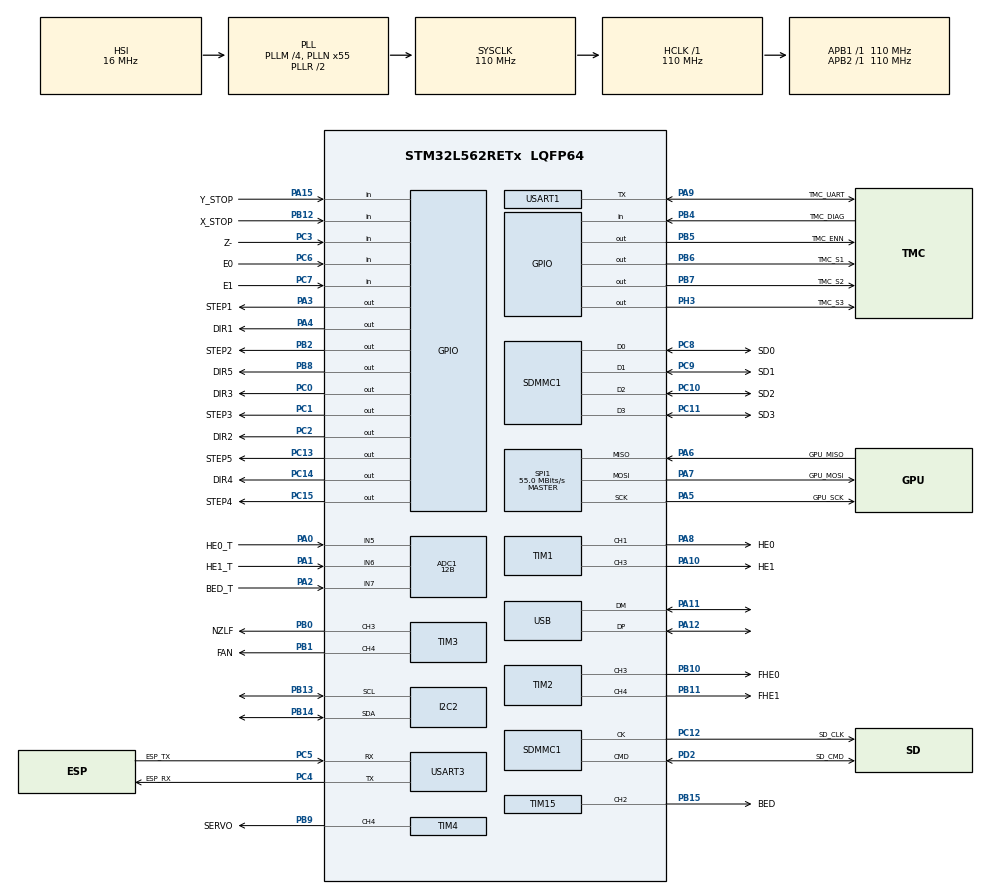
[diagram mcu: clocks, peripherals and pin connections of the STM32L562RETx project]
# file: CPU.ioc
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ADC1.Channel-0\#ChannelRegularConversion=ADC_CHANNEL_5
ADC1.Channel-1\#ChannelRegularConversion=ADC_CHANNEL_6
ADC1.Channel-2\#ChannelRegularConversion=ADC_CHANNEL_7
ADC1.Channel-3\#ChannelRegularConversion=ADC_CHANNEL_TEMPSENSOR
ADC1.Channel-4\#ChannelRegularConversion=ADC_CHANNEL_VBAT
ADC1.Channel-5\#ChannelRegularConversion=ADC_CHANNEL_VREFINT
ADC1.ContinuousConvMode=ENABLE
ADC1.DMAContinuousRequests=ENABLE
ADC1.NbrOfConversion=6
ADC1.NbrOfConversionFlag=1
ADC1.OffsetNumber-0\#ChannelRegularConversion=ADC_OFFSET_NONE
ADC1.OffsetNumber-1\#ChannelRegularConversion=ADC_OFFSET_NONE
ADC1.OffsetNumber-2\#ChannelRegularConversion=ADC_OFFSET_NONE
ADC1.OffsetNumber-3\#ChannelRegularConversion=ADC_OFFSET_NONE
ADC1.OffsetNumber-4\#ChannelRegularConversion=ADC_OFFSET_NONE
ADC1.OffsetNumber-5\#ChannelRegularConversion=ADC_OFFSET_NONE
ADC1.OversamplingMode=ENABLE
ADC1.Rank-0\#ChannelRegularConversion=1
ADC1.Rank-1\#ChannelRegularConversion=2
ADC1.Rank-2\#ChannelRegularConversion=3
ADC1.Rank-3\#ChannelRegularConversion=4
ADC1.Rank-4\#ChannelRegularConversion=5
ADC1.Rank-5\#ChannelRegularConversion=6
ADC1.Ratio=ADC_OVERSAMPLING_RATIO_16
ADC1.Resolution=ADC_RESOLUTION_12B
ADC1.SamplingTime-0\#ChannelRegularConversion=ADC_SAMPLETIME_640CYCLES_5
ADC1.SamplingTime-1\#ChannelRegularConversion=ADC_SAMPLETIME_640CYCLES_5
ADC1.SamplingTime-2\#ChannelRegularConversion=ADC_SAMPLETIME_640CYCLES_5
ADC1.SamplingTime-3\#ChannelRegularConversion=ADC_SAMPLETIME_640CYCLES_5
ADC1.SamplingTime-4\#ChannelRegularConversion=ADC_SAMPLETIME_640CYCLES_5
ADC1.SamplingTime-5\#ChannelRegularConversion=ADC_SAMPLETIME_640CYCLES_5
ADC1.master=1
Dma.ADC1.0.Channel_PRIV_NPRIV=DMA_CHANNEL_NPRIV_DISABLE
Dma.ADC1.0.Direction=DMA_PERIPH_TO_MEMORY
Dma.ADC1.0.EventEnable=DISABLE
Dma.ADC1.0.Instance=DMA1_Channel1
Dma.ADC1.0.MemDataAlignment=DMA_MDATAALIGN_WORD
Dma.ADC1.0.MemInc=DMA_MINC_ENABLE
Dma.ADC1.0.Mode=DMA_CIRCULAR
Dma.ADC1.0.PeriphDataAlignment=DMA_PDATAALIGN_WORD
Dma.ADC1.0.PeriphInc=DMA_PINC_DISABLE
Dma.ADC1.0.Polarity=HAL_DMAMUX_REQ_GEN_RISING
Dma.ADC1.0.Priority=DMA_PRIORITY_LOW
Dma.ADC1.0.RequestNumber=1
Dma.ADC1.0.SignalID=NONE
Dma.ADC1.0.SyncEnable=DISABLE
Dma.ADC1.0.SyncPolarity=HAL_DMAMUX_SYNC_NO_EVENT
Dma.ADC1.0.SyncRequestNumber=1
Dma.ADC1.0.SyncSignalID=NONE
Dma.Request0=ADC1
I2C2.Timing=0x40505681
Mcu.Family=STM32L5
Mcu.Name=STM32L562RETx
Mcu.Package=LQFP64
NVIC.DMA1_Channel1_IRQn=true\:0\:0\:false\:false\:true\:false\:true\:true
NVIC.PriorityGroup=NVIC_PRIORITYGROUP_3
NVIC.USB_FS_IRQn=true\:0\:0\:false\:false\:true\:false\:true\:true
PA0.GPIO_Label=HE0_T
PA0.Signal=ADCx_IN5
PA1.GPIO_Label=HE1_T
PA1.Signal=ADCx_IN6
PA10.GPIO_Label=HE1
PA10.Signal=S_TIM1_CH3
PA11.Mode=Device
PA11.Signal=USB_DM
PA12.Mode=Device
PA12.Signal=USB_DP
PA13\ (JTMS/SWDIO).Mode=Trace_Asynchronous_SW
PA13\ (JTMS/SWDIO).Signal=DEBUG_JTMS-SWDIO
PA14\ (JTCK/SWCLK).Mode=Trace_Asynchronous_SW
PA14\ (JTCK/SWCLK).Signal=DEBUG_JTCK-SWCLK
PA15\ (JTDI).GPIO_Label=Y_STOP
PA15\ (JTDI).Signal=GPIO_Input
PA2.GPIO_Label=BED_T
PA2.Signal=ADCx_IN7
PA3.GPIO_Label=STEP1
PA3.Signal=GPIO_Output
PA4.GPIO_Label=DIR1
PA4.Signal=GPIO_Output
PA5.GPIO_Label=GPU_SCK
PA5.Mode=Full_Duplex_Master
PA5.Signal=SPI1_SCK
PA6.GPIO_Label=GPU_MISO
PA6.Mode=Full_Duplex_Master
PA6.Signal=SPI1_MISO
PA7.GPIO_Label=GPU_MOSI
PA7.Mode=Full_Duplex_Master
PA7.Signal=SPI1_MOSI
PA8.GPIO_Label=HE0
PA8.Signal=S_TIM1_CH1
PA9.GPIO_Label=TMC_UART
PA9.Mode=Half_duplex(single_wire_mode)
PA9.Signal=USART1_TX
PB0.GPIO_Label=NZLF
PB0.Signal=S_TIM3_CH3
PB1.GPIO_Label=FAN
PB1.Signal=S_TIM3_CH4
PB10.GPIO_Label=FHE0
PB10.Signal=S_TIM2_CH3
PB11.GPIO_Label=FHE1
PB11.Signal=S_TIM2_CH4
PB12.GPIO_Label=X_STOP
PB12.Signal=GPIO_Input
PB13.Mode=I2C
PB13.Signal=I2C2_SCL
PB14.Mode=I2C
PB14.Signal=I2C2_SDA
PB15.GPIO_Label=BED
PB15.Signal=S_TIM15_CH2
PB2.GPIO_Label=STEP2
PB2.Signal=GPIO_Output
PB3\ (JTDO/TRACESWO).Mode=Trace_Asynchronous_SW
PB3\ (JTDO/TRACESWO).Signal=DEBUG_JTDO-SWO
PB4\ (NJTRST).GPIO_Label=TMC_DIAG
PB4\ (NJTRST).Signal=GPIO_Input
PB5.GPIO_Label=TMC_ENN
PB5.Signal=GPIO_Output
PB6.GPIO_Label=TMC_S1
PB6.Signal=GPIO_Output
PB7.GPIO_Label=TMC_S2
PB7.Signal=GPIO_Output
PB8.GPIO_Label=DIR5
PB8.Signal=GPIO_Output
PB9.GPIO_Label=SERVO
PB9.Signal=S_TIM4_CH4
PC0.GPIO_Label=DIR3
PC0.Signal=GPIO_Output
PC1.GPIO_Label=STEP3
PC1.Signal=GPIO_Output
PC10.GPIO_Label=SD2
PC10.Mode=mmc_4_bits_Wide_bus
PC10.Signal=SDMMC1_D2
PC11.GPIO_Label=SD3
PC11.Mode=mmc_4_bits_Wide_bus
PC11.Signal=SDMMC1_D3
PC12.GPIO_Label=SD_CLK
PC12.Mode=mmc_4_bits_Wide_bus
PC12.Signal=SDMMC1_CK
PC13.GPIO_Label=STEP5
PC13.Signal=GPIO_Output
PC14-OSC32_IN\ (PC14).GPIO_Label=DIR4
PC14-OSC32_IN\ (PC14).Signal=GPIO_Output
PC15-OSC32_OUT\ (PC15).GPIO_Label=STEP4
PC15-OSC32_OUT\ (PC15).Signal=GPIO_Output
PC2.GPIO_Label=DIR2
PC2.Signal=GPIO_Output
PC3.GPIO_Label=Z-
PC3.Signal=GPIO_Input
PC4.GPIO_Label=ESP_RX
PC4.Mode=Asynchronous
PC4.Signal=USART3_TX
PC5.GPIO_Label=ESP_TX
PC5.Mode=Asynchronous
PC5.Signal=USART3_RX
PC6.GPIO_Label=E0
PC6.Signal=GPIO_Input
PC7.GPIO_Label=E1
PC7.Signal=GPIO_Input
PC8.GPIO_Label=SD0
PC8.Mode=mmc_4_bits_Wide_bus
PC8.Signal=SDMMC1_D0
PC9.GPIO_Label=SD1
PC9.Mode=mmc_4_bits_Wide_bus
PC9.Signal=SDMMC1_D1
PD2.GPIO_Label=SD_CMD
PD2.Mode=mmc_4_bits_Wide_bus
PD2.Signal=SDMMC1_CMD
PH3-BOOT0.GPIO_Label=TMC_S3
PH3-BOOT0.Signal=GPIO_Output
ProjectManager.HeapSize=0x200
ProjectManager.StackSize=0x400
ProjectManager.TargetToolchain=STM32CubeIDE
RCC.ADCCLockSelection=RCC_ADCCLKSOURCE_SYSCLK
RCC.ADCFreq_Value=110000000
RCC.AHBFreq_Value=110000000
RCC.APB1Freq_Value=110000000
RCC.APB1TimFreq_Value=110000000
RCC.APB2Freq_Value=110000000
RCC.APB2TimFreq_Value=110000000
RCC.CortexFreq_Value=110000000
RCC.HCLKFreq_Value=110000000
RCC.HSE_VALUE=48000000
RCC.HSI48_VALUE=48000000
RCC.HSI_VALUE=16000000
RCC.LSE_VALUE=32768
RCC.MSIClockRange=RCC_MSIRANGE_11
RCC.MSI_VALUE=48000000
RCC.PLLM=4
RCC.PLLN=55
RCC.PLLSAI1M=6
RCC.PLLSAI1N=12
RCC.PLLSAI1Source=RCC_PLLSAI1SOURCE_HSE
RCC.PLLSourceVirtual=RCC_PLLSOURCE_HSI
RCC.SYSCLKFreq_VALUE=110000000
RCC.SYSCLKSource=RCC_SYSCLKSOURCE_PLLCLK
RCC.USBFreq_Value=48000000
RCC.VCOOutputFreq_Value=220000000
SH.ADCx_IN5.0=ADC1_IN5,IN5-Single-Ended
SH.ADCx_IN6.0=ADC1_IN6,IN6-Single-Ended
SH.ADCx_IN7.0=ADC1_IN7,IN7-Single-Ended
SH.S_TIM15_CH2.0=TIM15_CH2,PWM Generation2 CH2
SH.S_TIM1_CH1.0=TIM1_CH1,PWM Generation1 CH1
SH.S_TIM1_CH3.0=TIM1_CH3,PWM Generation3 CH3
SH.S_TIM2_CH3.0=TIM2_CH3,PWM Generation3 CH3
SH.S_TIM2_CH4.0=TIM2_CH4,PWM Generation4 CH4
SH.S_TIM3_CH3.0=TIM3_CH3,PWM Generation3 CH3
SH.S_TIM3_CH4.0=TIM3_CH4,PWM Generation4 CH4
SH.S_TIM4_CH4.0=TIM4_CH4,PWM Generation4 CH4
SPI1.BaudRatePrescaler=SPI_BAUDRATEPRESCALER_2
SPI1.CalculateBaudRate=55.0 MBits/s
SPI1.Direction=SPI_DIRECTION_2LINES
SPI1.Mode=SPI_MODE_MASTER
SPI1.VirtualType=VM_MASTER
TIM1.Channel-PWM\ Generation1\ CH1=TIM_CHANNEL_1
TIM1.Channel-PWM\ Generation3\ CH3=TIM_CHANNEL_3
TIM15.Channel-PWM\ Generation2\ CH2=TIM_CHANNEL_2
TIM2.Channel-PWM\ Generation3\ CH3=TIM_CHANNEL_3
TIM2.Channel-PWM\ Generation4\ CH4=TIM_CHANNEL_4
TIM3.Channel-PWM\ Generation3\ CH3=TIM_CHANNEL_3
TIM3.Channel-PWM\ Generation4\ CH4=TIM_CHANNEL_4
TIM4.Channel-PWM\ Generation4\ CH4=TIM_CHANNEL_4
USART1.VirtualMode-Half_duplex(single_wire_mode)=VM_ASYNC
USART3.VirtualMode-Asynchronous=VM_ASYNC
USB_DEVICE.CLASS_NAME_FS=CDC
USB_DEVICE.VirtualMode=Cdc
USB_DEVICE.VirtualModeFS=Cdc_FS
VP_ADC1_TempSens_Input.Mode=IN-TempSens
VP_ADC1_Vbat_Input.Mode=IN-Vbat
VP_ADC1_Vref_Input.Mode=IN-Vrefint
VP_PWR_VS_DBSignals.Mode=DisableDeadBatterySignals
VP_PWR_VS_SECSignals.Mode=Security/Privilege
VP_USB_DEVICE_VS_USB_DEVICE_CDC_FS.Mode=CDC_FS
board=custom

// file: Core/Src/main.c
/* USER CODE BEGIN Header */
/**
  ******************************************************************************
  * @file           : main.c
  * @brief          : Main program body
  ******************************************************************************
  * @attention
  *
  * Copyright (c) 2023 STMicroelectronics.
  * All rights reserved.
  *
  * This software is licensed under terms that can be found in the LICENSE file
  * in the root directory of this software component.
  * If no LICENSE file comes with this software, it is provided AS-IS.
  *
  ******************************************************************************
  */
/* USER CODE END Header */
#include "main.h"
#include "usb_device.h"

/* USER CODE BEGIN Includes */
#include <stdio.h>
#include <string.h>
#include <ctype.h>
#include <stdarg.h>
/* USER CODE END Includes */

/* USER CODE BEGIN PD */
#define ADC_CHANNELS 6
/* USER CODE END PD */

ADC_HandleTypeDef hadc1;
DMA_HandleTypeDef hdma_adc1;

I2C_HandleTypeDef hi2c2;

MMC_HandleTypeDef hmmc1;

SPI_HandleTypeDef hspi1;

TIM_HandleTypeDef htim1;
TIM_HandleTypeDef htim2;
TIM_HandleTypeDef htim3;
TIM_HandleTypeDef htim4;
TIM_HandleTypeDef htim15;

UART_HandleTypeDef huart1;
UART_HandleTypeDef huart3;

/* USER CODE BEGIN PV */
uint32_t value[ADC_CHANNELS];
/* USER CODE END PV */

void SystemClock_Config(void);
static void MX_GPIO_Init(void);
static void MX_DMA_Init(void);
static void MX_I2C2_Init(void);
static void MX_SDMMC1_MMC_Init(void);
static void MX_SPI1_Init(void);
static void MX_TIM1_Init(void);
static void MX_TIM2_Init(void);
static void MX_TIM3_Init(void);
static void MX_TIM4_Init(void);
static void MX_TIM15_Init(void);
static void MX_USART1_UART_Init(void);
static void MX_USART3_UART_Init(void);
static void MX_ADC1_Init(void);

int main(void)
{

  /* MCU Configuration--------------------------------------------------------*/

  /* Reset of all peripherals, Initializes the Flash interface and the Systick. */
  HAL_Init();

  /* Configure the system clock */
  SystemClock_Config();

  /* Initialize all configured peripherals */
  MX_GPIO_Init();
  MX_DMA_Init();
  MX_I2C2_Init();
  MX_SDMMC1_MMC_Init();
  MX_SPI1_Init();
  MX_TIM1_Init();
  MX_TIM2_Init();
  MX_TIM3_Init();
  MX_TIM4_Init();
  MX_TIM15_Init();
  MX_USART1_UART_Init();
  MX_USART3_UART_Init();
  MX_ADC1_Init();
  MX_USB_Device_Init();
  /* USER CODE BEGIN 2 */
//  HAL_ADC_Start_DMA(&hadc1, value, ADC_CHANNELS);
  /* USER CODE END 2 */

  /* Infinite loop */
  /* USER CODE BEGIN WHILE */
  while (1)
  {
//	  uint8_t Test[] = "Hello World !!!\r\n"; //Data to send
//	  HAL_UART_Transmit(&huart3,value[0],sizeof(value[0]),10);// Sending in normal mode
	  HAL_Delay(1000);
    /* USER CODE END WHILE */

  }
}

void SystemClock_Config(void)
{
  RCC_OscInitTypeDef RCC_OscInitStruct = {0};
  RCC_ClkInitTypeDef RCC_ClkInitStruct = {0};

  /** Configure the main internal regulator output voltage
  */
  if (HAL_PWREx_ControlVoltageScaling(PWR_REGULATOR_VOLTAGE_SCALE0) != HAL_OK)
  {
    Error_Handler();
  }

  /** Initializes the RCC Oscillators according to the specified parameters
  * in the RCC_OscInitTypeDef structure.
  */
  RCC_OscInitStruct.OscillatorType = RCC_OSCILLATORTYPE_HSI|RCC_OSCILLATORTYPE_HSE;
  RCC_OscInitStruct.HSEState = RCC_HSE_OFF;
  RCC_OscInitStruct.HSIState = RCC_HSI_ON;
  RCC_OscInitStruct.HSICalibrationValue = RCC_HSICALIBRATION_DEFAULT;
  RCC_OscInitStruct.PLL.PLLState = RCC_PLL_ON;
  RCC_OscInitStruct.PLL.PLLSource = RCC_PLLSOURCE_HSI;
  RCC_OscInitStruct.PLL.PLLM = 4;
  RCC_OscInitStruct.PLL.PLLN = 55;
  RCC_OscInitStruct.PLL.PLLP = RCC_PLLP_DIV7;
  RCC_OscInitStruct.PLL.PLLQ = RCC_PLLQ_DIV2;
  RCC_OscInitStruct.PLL.PLLR = RCC_PLLR_DIV2;
  if (HAL_RCC_OscConfig(&RCC_OscInitStruct) != HAL_OK)
  {
    Error_Handler();
  }

  /** Initializes the CPU, AHB and APB buses clocks
  */
  RCC_ClkInitStruct.ClockType = RCC_CLOCKTYPE_HCLK|RCC_CLOCKTYPE_SYSCLK
                              |RCC_CLOCKTYPE_PCLK1|RCC_CLOCKTYPE_PCLK2;
  RCC_ClkInitStruct.SYSCLKSource = RCC_SYSCLKSOURCE_PLLCLK;
  RCC_ClkInitStruct.AHBCLKDivider = RCC_SYSCLK_DIV1;
  RCC_ClkInitStruct.APB1CLKDivider = RCC_HCLK_DIV1;
  RCC_ClkInitStruct.APB2CLKDivider = RCC_HCLK_DIV1;

  if (HAL_RCC_ClockConfig(&RCC_ClkInitStruct, FLASH_LATENCY_5) != HAL_OK)
  {
    Error_Handler();
  }
}

static void MX_ADC1_Init(void)
{

  ADC_MultiModeTypeDef multimode = {0};
  ADC_ChannelConfTypeDef sConfig = {0};

  /** Common config
  */
  hadc1.Instance = ADC1;
  hadc1.Init.ClockPrescaler = ADC_CLOCK_ASYNC_DIV1;
  hadc1.Init.Resolution = ADC_RESOLUTION_12B;
  hadc1.Init.DataAlign = ADC_DATAALIGN_RIGHT;
  hadc1.Init.ScanConvMode = ADC_SCAN_ENABLE;
  hadc1.Init.EOCSelection = ADC_EOC_SINGLE_CONV;
  hadc1.Init.LowPowerAutoWait = DISABLE;
  hadc1.Init.ContinuousConvMode = ENABLE;
  hadc1.Init.NbrOfConversion = 6;
  hadc1.Init.DiscontinuousConvMode = DISABLE;
  hadc1.Init.ExternalTrigConv = ADC_SOFTWARE_START;
  hadc1.Init.ExternalTrigConvEdge = ADC_EXTERNALTRIGCONVEDGE_NONE;
  hadc1.Init.DMAContinuousRequests = ENABLE;
  hadc1.Init.Overrun = ADC_OVR_DATA_PRESERVED;
  hadc1.Init.OversamplingMode = ENABLE;
  hadc1.Init.Oversampling.Ratio = ADC_OVERSAMPLING_RATIO_16;
  hadc1.Init.Oversampling.RightBitShift = ADC_RIGHTBITSHIFT_NONE;
  hadc1.Init.Oversampling.TriggeredMode = ADC_TRIGGEREDMODE_SINGLE_TRIGGER;
  hadc1.Init.Oversampling.OversamplingStopReset = ADC_REGOVERSAMPLING_CONTINUED_MODE;
  if (HAL_ADC_Init(&hadc1) != HAL_OK)
  {
    Error_Handler();
  }

  /** Configure the ADC multi-mode
  */
  multimode.Mode = ADC_MODE_INDEPENDENT;
  if (HAL_ADCEx_MultiModeConfigChannel(&hadc1, &multimode) != HAL_OK)
  {
    Error_Handler();
  }

  /** Configure Regular Channel
  */
  sConfig.Channel = ADC_CHANNEL_5;
  sConfig.Rank = ADC_REGULAR_RANK_1;
  sConfig.SamplingTime = ADC_SAMPLETIME_640CYCLES_5;
  sConfig.SingleDiff = ADC_SINGLE_ENDED;
  sConfig.OffsetNumber = ADC_OFFSET_NONE;
  sConfig.Offset = 0;
  if (HAL_ADC_ConfigChannel(&hadc1, &sConfig) != HAL_OK)
  {
    Error_Handler();
  }

  /** Configure Regular Channel
  */
  sConfig.Channel = ADC_CHANNEL_6;
  sConfig.Rank = ADC_REGULAR_RANK_2;
  if (HAL_ADC_ConfigChannel(&hadc1, &sConfig) != HAL_OK)
  {
    Error_Handler();
  }

  /** Configure Regular Channel
  */
  sConfig.Channel = ADC_CHANNEL_7;
  sConfig.Rank = ADC_REGULAR_RANK_3;
  if (HAL_ADC_ConfigChannel(&hadc1, &sConfig) != HAL_OK)
  {
    Error_Handler();
  }

  /** Configure Regular Channel
  */
  sConfig.Channel = ADC_CHANNEL_TEMPSENSOR;
  sConfig.Rank = ADC_REGULAR_RANK_4;
  if (HAL_ADC_ConfigChannel(&hadc1, &sConfig) != HAL_OK)
  {
    Error_Handler();
  }

  /** Configure Regular Channel
  */
  sConfig.Channel = ADC_CHANNEL_VBAT;
  sConfig.Rank = ADC_REGULAR_RANK_5;
  if (HAL_ADC_ConfigChannel(&hadc1, &sConfig) != HAL_OK)
  {
    Error_Handler();
  }

  /** Configure Regular Channel
  */
  sConfig.Channel = ADC_CHANNEL_VREFINT;
  sConfig.Rank = ADC_REGULAR_RANK_6;
  if (HAL_ADC_ConfigChannel(&hadc1, &sConfig) != HAL_OK)
  {
    Error_Handler();
  }

}

static void MX_I2C2_Init(void)
{

  hi2c2.Instance = I2C2;
  hi2c2.Init.Timing = 0x40505681;
  hi2c2.Init.OwnAddress1 = 0;
  hi2c2.Init.AddressingMode = I2C_ADDRESSINGMODE_7BIT;
  hi2c2.Init.DualAddressMode = I2C_DUALADDRESS_DISABLE;
  hi2c2.Init.OwnAddress2 = 0;
  hi2c2.Init.OwnAddress2Masks = I2C_OA2_NOMASK;
  hi2c2.Init.GeneralCallMode = I2C_GENERALCALL_DISABLE;
  hi2c2.Init.NoStretchMode = I2C_NOSTRETCH_DISABLE;
  if (HAL_I2C_Init(&hi2c2) != HAL_OK)
  {
    Error_Handler();
  }

  /** Configure Analogue filter
  */
  if (HAL_I2CEx_ConfigAnalogFilter(&hi2c2, I2C_ANALOGFILTER_ENABLE) != HAL_OK)
  {
    Error_Handler();
  }

  /** Configure Digital filter
  */
  if (HAL_I2CEx_ConfigDigitalFilter(&hi2c2, 0) != HAL_OK)
  {
    Error_Handler();
  }

}

static void MX_SDMMC1_MMC_Init(void)
{

  hmmc1.Instance = SDMMC1;
  hmmc1.Init.ClockEdge = SDMMC_CLOCK_EDGE_RISING;
  hmmc1.Init.ClockPowerSave = SDMMC_CLOCK_POWER_SAVE_DISABLE;
  hmmc1.Init.BusWide = SDMMC_BUS_WIDE_4B;
  hmmc1.Init.HardwareFlowControl = SDMMC_HARDWARE_FLOW_CONTROL_DISABLE;
  hmmc1.Init.ClockDiv = 0;
  if (HAL_MMC_Init(&hmmc1) != HAL_OK)
  {
    Error_Handler();
  }

}

static void MX_SPI1_Init(void)
{

  /* SPI1 parameter configuration*/
  hspi1.Instance = SPI1;
  hspi1.Init.Mode = SPI_MODE_MASTER;
  hspi1.Init.Direction = SPI_DIRECTION_2LINES;
  hspi1.Init.DataSize = SPI_DATASIZE_4BIT;
  hspi1.Init.CLKPolarity = SPI_POLARITY_LOW;
  hspi1.Init.CLKPhase = SPI_PHASE_1EDGE;
  hspi1.Init.NSS = SPI_NSS_SOFT;
  hspi1.Init.BaudRatePrescaler = SPI_BAUDRATEPRESCALER_2;
  hspi1.Init.FirstBit = SPI_FIRSTBIT_MSB;
  hspi1.Init.TIMode = SPI_TIMODE_DISABLE;
  hspi1.Init.CRCCalculation = SPI_CRCCALCULATION_DISABLE;
  hspi1.Init.CRCPolynomial = 7;
  hspi1.Init.CRCLength = SPI_CRC_LENGTH_DATASIZE;
  hspi1.Init.NSSPMode = SPI_NSS_PULSE_ENABLE;
  if (HAL_SPI_Init(&hspi1) != HAL_OK)
  {
    Error_Handler();
  }

}

static void MX_TIM1_Init(void)
{

  TIM_MasterConfigTypeDef sMasterConfig = {0};
  TIM_OC_InitTypeDef sConfigOC = {0};
  TIM_BreakDeadTimeConfigTypeDef sBreakDeadTimeConfig = {0};

  htim1.Instance = TIM1;
  htim1.Init.Prescaler = 0;
  htim1.Init.CounterMode = TIM_COUNTERMODE_UP;
  htim1.Init.Period = 65535;
  htim1.Init.ClockDivision = TIM_CLOCKDIVISION_DIV1;
  htim1.Init.RepetitionCounter = 0;
  htim1.Init.AutoReloadPreload = TIM_AUTORELOAD_PRELOAD_DISABLE;
  if (HAL_TIM_PWM_Init(&htim1) != HAL_OK)
  {
    Error_Handler();
  }
  sMasterConfig.MasterOutputTrigger = TIM_TRGO_RESET;
  sMasterConfig.MasterOutputTrigger2 = TIM_TRGO2_RESET;
  sMasterConfig.MasterSlaveMode = TIM_MASTERSLAVEMODE_DISABLE;
  if (HAL_TIMEx_MasterConfigSynchronization(&htim1, &sMasterConfig) != HAL_OK)
  {
    Error_Handler();
  }
  sConfigOC.OCMode = TIM_OCMODE_PWM1;
  sConfigOC.Pulse = 0;
  sConfigOC.OCPolarity = TIM_OCPOLARITY_HIGH;
  sConfigOC.OCNPolarity = TIM_OCNPOLARITY_HIGH;
  sConfigOC.OCFastMode = TIM_OCFAST_DISABLE;
  sConfigOC.OCIdleState = TIM_OCIDLESTATE_RESET;
  sConfigOC.OCNIdleState = TIM_OCNIDLESTATE_RESET;
  if (HAL_TIM_PWM_ConfigChannel(&htim1, &sConfigOC, TIM_CHANNEL_1) != HAL_OK)
  {
    Error_Handler();
  }
  if (HAL_TIM_PWM_ConfigChannel(&htim1, &sConfigOC, TIM_CHANNEL_3) != HAL_OK)
  {
    Error_Handler();
  }
  sBreakDeadTimeConfig.OffStateRunMode = TIM_OSSR_DISABLE;
  sBreakDeadTimeConfig.OffStateIDLEMode = TIM_OSSI_DISABLE;
  sBreakDeadTimeConfig.LockLevel = TIM_LOCKLEVEL_OFF;
  sBreakDeadTimeConfig.DeadTime = 0;
  sBreakDeadTimeConfig.BreakState = TIM_BREAK_DISABLE;
  sBreakDeadTimeConfig.BreakPolarity = TIM_BREAKPOLARITY_HIGH;
  sBreakDeadTimeConfig.BreakFilter = 0;
  sBreakDeadTimeConfig.BreakAFMode = TIM_BREAK_AFMODE_INPUT;
  sBreakDeadTimeConfig.Break2State = TIM_BREAK2_DISABLE;
  sBreakDeadTimeConfig.Break2Polarity = TIM_BREAK2POLARITY_HIGH;
  sBreakDeadTimeConfig.Break2Filter = 0;
  sBreakDeadTimeConfig.Break2AFMode = TIM_BREAK_AFMODE_INPUT;
  sBreakDeadTimeConfig.AutomaticOutput = TIM_AUTOMATICOUTPUT_DISABLE;
  if (HAL_TIMEx_ConfigBreakDeadTime(&htim1, &sBreakDeadTimeConfig) != HAL_OK)
  {
    Error_Handler();
  }
  HAL_TIM_MspPostInit(&htim1);

}

static void MX_TIM2_Init(void)
{

  TIM_MasterConfigTypeDef sMasterConfig = {0};
  TIM_OC_InitTypeDef sConfigOC = {0};

  htim2.Instance = TIM2;
  htim2.Init.Prescaler = 0;
  htim2.Init.CounterMode = TIM_COUNTERMODE_UP;
  htim2.Init.Period = 4294967295;
  htim2.Init.ClockDivision = TIM_CLOCKDIVISION_DIV1;
  htim2.Init.AutoReloadPreload = TIM_AUTORELOAD_PRELOAD_DISABLE;
  if (HAL_TIM_PWM_Init(&htim2) != HAL_OK)
  {
    Error_Handler();
  }
  sMasterConfig.MasterOutputTrigger = TIM_TRGO_RESET;
  sMasterConfig.MasterSlaveMode = TIM_MASTERSLAVEMODE_DISABLE;
  if (HAL_TIMEx_MasterConfigSynchronization(&htim2, &sMasterConfig) != HAL_OK)
  {
    Error_Handler();
  }
  sConfigOC.OCMode = TIM_OCMODE_PWM1;
  sConfigOC.Pulse = 0;
  sConfigOC.OCPolarity = TIM_OCPOLARITY_HIGH;
  sConfigOC.OCFastMode = TIM_OCFAST_DISABLE;
  if (HAL_TIM_PWM_ConfigChannel(&htim2, &sConfigOC, TIM_CHANNEL_3) != HAL_OK)
  {
    Error_Handler();
  }
  if (HAL_TIM_PWM_ConfigChannel(&htim2, &sConfigOC, TIM_CHANNEL_4) != HAL_OK)
  {
    Error_Handler();
  }
  HAL_TIM_MspPostInit(&htim2);

}

static void MX_TIM3_Init(void)
{

  TIM_MasterConfigTypeDef sMasterConfig = {0};
  TIM_OC_InitTypeDef sConfigOC = {0};

  htim3.Instance = TIM3;
  htim3.Init.Prescaler = 0;
  htim3.Init.CounterMode = TIM_COUNTERMODE_UP;
  htim3.Init.Period = 65535;
  htim3.Init.ClockDivision = TIM_CLOCKDIVISION_DIV1;
  htim3.Init.AutoReloadPreload = TIM_AUTORELOAD_PRELOAD_DISABLE;
  if (HAL_TIM_PWM_Init(&htim3) != HAL_OK)
  {
    Error_Handler();
  }
  sMasterConfig.MasterOutputTrigger = TIM_TRGO_RESET;
  sMasterConfig.MasterSlaveMode = TIM_MASTERSLAVEMODE_DISABLE;
  if (HAL_TIMEx_MasterConfigSynchronization(&htim3, &sMasterConfig) != HAL_OK)
  {
    Error_Handler();
  }
  sConfigOC.OCMode = TIM_OCMODE_PWM1;
  sConfigOC.Pulse = 0;
  sConfigOC.OCPolarity = TIM_OCPOLARITY_HIGH;
  sConfigOC.OCFastMode = TIM_OCFAST_DISABLE;
  if (HAL_TIM_PWM_ConfigChannel(&htim3, &sConfigOC, TIM_CHANNEL_3) != HAL_OK)
  {
    Error_Handler();
  }
  if (HAL_TIM_PWM_ConfigChannel(&htim3, &sConfigOC, TIM_CHANNEL_4) != HAL_OK)
  {
    Error_Handler();
  }
  HAL_TIM_MspPostInit(&htim3);

}

static void MX_TIM4_Init(void)
{

  TIM_MasterConfigTypeDef sMasterConfig = {0};
  TIM_OC_InitTypeDef sConfigOC = {0};

  htim4.Instance = TIM4;
  htim4.Init.Prescaler = 0;
  htim4.Init.CounterMode = TIM_COUNTERMODE_UP;
  htim4.Init.Period = 65535;
  htim4.Init.ClockDivision = TIM_CLOCKDIVISION_DIV1;
  htim4.Init.AutoReloadPreload = TIM_AUTORELOAD_PRELOAD_DISABLE;
  if (HAL_TIM_PWM_Init(&htim4) != HAL_OK)
  {
    Error_Handler();
  }
  sMasterConfig.MasterOutputTrigger = TIM_TRGO_RESET;
  sMasterConfig.MasterSlaveMode = TIM_MASTERSLAVEMODE_DISABLE;
  if (HAL_TIMEx_MasterConfigSynchronization(&htim4, &sMasterConfig) != HAL_OK)
  {
    Error_Handler();
  }
  sConfigOC.OCMode = TIM_OCMODE_PWM1;
  sConfigOC.Pulse = 0;
  sConfigOC.OCPolarity = TIM_OCPOLARITY_HIGH;
  sConfigOC.OCFastMode = TIM_OCFAST_DISABLE;
  if (HAL_TIM_PWM_ConfigChannel(&htim4, &sConfigOC, TIM_CHANNEL_4) != HAL_OK)
  {
    Error_Handler();
  }
  HAL_TIM_MspPostInit(&htim4);

}

static void MX_TIM15_Init(void)
{

  TIM_MasterConfigTypeDef sMasterConfig = {0};
  TIM_OC_InitTypeDef sConfigOC = {0};
  TIM_BreakDeadTimeConfigTypeDef sBreakDeadTimeConfig = {0};

  htim15.Instance = TIM15;
  htim15.Init.Prescaler = 0;
  htim15.Init.CounterMode = TIM_COUNTERMODE_UP;
  htim15.Init.Period = 65535;
  htim15.Init.ClockDivision = TIM_CLOCKDIVISION_DIV1;
  htim15.Init.RepetitionCounter = 0;
  htim15.Init.AutoReloadPreload = TIM_AUTORELOAD_PRELOAD_DISABLE;
  if (HAL_TIM_PWM_Init(&htim15) != HAL_OK)
  {
    Error_Handler();
  }
  sMasterConfig.MasterOutputTrigger = TIM_TRGO_RESET;
  sMasterConfig.MasterSlaveMode = TIM_MASTERSLAVEMODE_DISABLE;
  if (HAL_TIMEx_MasterConfigSynchronization(&htim15, &sMasterConfig) != HAL_OK)
  {
    Error_Handler();
  }
  sConfigOC.OCMode = TIM_OCMODE_PWM1;
  sConfigOC.Pulse = 0;
  sConfigOC.OCPolarity = TIM_OCPOLARITY_HIGH;
  sConfigOC.OCNPolarity = TIM_OCNPOLARITY_HIGH;
  sConfigOC.OCFastMode = TIM_OCFAST_DISABLE;
  sConfigOC.OCIdleState = TIM_OCIDLESTATE_RESET;
  sConfigOC.OCNIdleState = TIM_OCNIDLESTATE_RESET;
  if (HAL_TIM_PWM_ConfigChannel(&htim15, &sConfigOC, TIM_CHANNEL_2) != HAL_OK)
  {
    Error_Handler();
  }
  sBreakDeadTimeConfig.OffStateRunMode = TIM_OSSR_DISABLE;
  sBreakDeadTimeConfig.OffStateIDLEMode = TIM_OSSI_DISABLE;
  sBreakDeadTimeConfig.LockLevel = TIM_LOCKLEVEL_OFF;
  sBreakDeadTimeConfig.DeadTime = 0;
  sBreakDeadTimeConfig.BreakState = TIM_BREAK_DISABLE;
  sBreakDeadTimeConfig.BreakPolarity = TIM_BREAKPOLARITY_HIGH;
  sBreakDeadTimeConfig.BreakFilter = 0;
  sBreakDeadTimeConfig.AutomaticOutput = TIM_AUTOMATICOUTPUT_DISABLE;
  if (HAL_TIMEx_ConfigBreakDeadTime(&htim15, &sBreakDeadTimeConfig) != HAL_OK)
  {
    Error_Handler();
  }
  HAL_TIM_MspPostInit(&htim15);

}

static void MX_USART1_UART_Init(void)
{

  huart1.Instance = USART1;
  huart1.Init.BaudRate = 115200;
  huart1.Init.WordLength = UART_WORDLENGTH_8B;
  huart1.Init.StopBits = UART_STOPBITS_1;
  huart1.Init.Parity = UART_PARITY_NONE;
  huart1.Init.Mode = UART_MODE_TX_RX;
  huart1.Init.HwFlowCtl = UART_HWCONTROL_NONE;
  huart1.Init.OverSampling = UART_OVERSAMPLING_16;
  huart1.Init.OneBitSampling = UART_ONE_BIT_SAMPLE_DISABLE;
  huart1.Init.ClockPrescaler = UART_PRESCALER_DIV1;
  huart1.AdvancedInit.AdvFeatureInit = UART_ADVFEATURE_NO_INIT;
  if (HAL_HalfDuplex_Init(&huart1) != HAL_OK)
  {
    Error_Handler();
  }
  if (HAL_UARTEx_SetTxFifoThreshold(&huart1, UART_TXFIFO_THRESHOLD_1_8) != HAL_OK)
  {
    Error_Handler();
  }
  if (HAL_UARTEx_SetRxFifoThreshold(&huart1, UART_RXFIFO_THRESHOLD_1_8) != HAL_OK)
  {
    Error_Handler();
  }
  if (HAL_UARTEx_DisableFifoMode(&huart1) != HAL_OK)
  {
    Error_Handler();
  }

}

static void MX_USART3_UART_Init(void)
{

  huart3.Instance = USART3;
  huart3.Init.BaudRate = 115200;
  huart3.Init.WordLength = UART_WORDLENGTH_8B;
  huart3.Init.StopBits = UART_STOPBITS_1;
  huart3.Init.Parity = UART_PARITY_NONE;
  huart3.Init.Mode = UART_MODE_TX_RX;
  huart3.Init.HwFlowCtl = UART_HWCONTROL_NONE;
  huart3.Init.OverSampling = UART_OVERSAMPLING_16;
  huart3.Init.OneBitSampling = UART_ONE_BIT_SAMPLE_DISABLE;
  huart3.Init.ClockPrescaler = UART_PRESCALER_DIV1;
  huart3.AdvancedInit.AdvFeatureInit = UART_ADVFEATURE_NO_INIT;
  if (HAL_UART_Init(&huart3) != HAL_OK)
  {
    Error_Handler();
  }
  if (HAL_UARTEx_SetTxFifoThreshold(&huart3, UART_TXFIFO_THRESHOLD_1_8) != HAL_OK)
  {
    Error_Handler();
  }
  if (HAL_UARTEx_SetRxFifoThreshold(&huart3, UART_RXFIFO_THRESHOLD_1_8) != HAL_OK)
  {
    Error_Handler();
  }
  if (HAL_UARTEx_DisableFifoMode(&huart3) != HAL_OK)
  {
    Error_Handler();
  }

}

static void MX_DMA_Init(void)
{

  /* DMA controller clock enable */
  __HAL_RCC_DMAMUX1_CLK_ENABLE();
  __HAL_RCC_DMA1_CLK_ENABLE();

  /* DMA interrupt init */
  /* DMA1_Channel1_IRQn interrupt configuration */
  HAL_NVIC_SetPriority(DMA1_Channel1_IRQn, 0, 0);
  HAL_NVIC_EnableIRQ(DMA1_Channel1_IRQn);

}

static void MX_GPIO_Init(void)
{
  GPIO_InitTypeDef GPIO_InitStruct = {0};

  /* GPIO Ports Clock Enable */
  __HAL_RCC_GPIOC_CLK_ENABLE();
  __HAL_RCC_GPIOA_CLK_ENABLE();
  __HAL_RCC_GPIOB_CLK_ENABLE();
  __HAL_RCC_GPIOD_CLK_ENABLE();
  __HAL_RCC_GPIOH_CLK_ENABLE();

  /*Configure GPIO pin Output Level */
  HAL_GPIO_WritePin(GPIOC, STEP5_Pin|DIR4_Pin|STEP4_Pin|DIR3_Pin
                          |STEP3_Pin|DIR2_Pin, GPIO_PIN_RESET);

  /*Configure GPIO pin Output Level */
  HAL_GPIO_WritePin(GPIOA, STEP1_Pin|DIR1_Pin, GPIO_PIN_RESET);

  /*Configure GPIO pin Output Level */
  HAL_GPIO_WritePin(GPIOB, STEP2_Pin|TMC_ENN_Pin|TMC_S1_Pin|TMC_S2_Pin
                          |DIR5_Pin, GPIO_PIN_RESET);

  /*Configure GPIO pin Output Level */
  HAL_GPIO_WritePin(TMC_S3_GPIO_Port, TMC_S3_Pin, GPIO_PIN_RESET);

  /*Configure GPIO pins : STEP5_Pin DIR4_Pin STEP4_Pin DIR3_Pin
                           STEP3_Pin DIR2_Pin */
  GPIO_InitStruct.Pin = STEP5_Pin|DIR4_Pin|STEP4_Pin|DIR3_Pin
                          |STEP3_Pin|DIR2_Pin;
  GPIO_InitStruct.Mode = GPIO_MODE_OUTPUT_PP;
  GPIO_InitStruct.Pull = GPIO_NOPULL;
  GPIO_InitStruct.Speed = GPIO_SPEED_FREQ_LOW;
  HAL_GPIO_Init(GPIOC, &GPIO_InitStruct);

  /*Configure GPIO pins : Z__Pin E0_Pin E1_Pin */
  GPIO_InitStruct.Pin = Z__Pin|E0_Pin|E1_Pin;
  GPIO_InitStruct.Mode = GPIO_MODE_INPUT;
  GPIO_InitStruct.Pull = GPIO_NOPULL;
  HAL_GPIO_Init(GPIOC, &GPIO_InitStruct);

  /*Configure GPIO pins : STEP1_Pin DIR1_Pin */
  GPIO_InitStruct.Pin = STEP1_Pin|DIR1_Pin;
  GPIO_InitStruct.Mode = GPIO_MODE_OUTPUT_PP;
  GPIO_InitStruct.Pull = GPIO_NOPULL;
  GPIO_InitStruct.Speed = GPIO_SPEED_FREQ_LOW;
  HAL_GPIO_Init(GPIOA, &GPIO_InitStruct);

  /*Configure GPIO pins : STEP2_Pin TMC_ENN_Pin TMC_S1_Pin TMC_S2_Pin
                           DIR5_Pin */
  GPIO_InitStruct.Pin = STEP2_Pin|TMC_ENN_Pin|TMC_S1_Pin|TMC_S2_Pin
                          |DIR5_Pin;
  GPIO_InitStruct.Mode = GPIO_MODE_OUTPUT_PP;
  GPIO_InitStruct.Pull = GPIO_NOPULL;
  GPIO_InitStruct.Speed = GPIO_SPEED_FREQ_LOW;
  HAL_GPIO_Init(GPIOB, &GPIO_InitStruct);

  /*Configure GPIO pins : X_STOP_Pin TMC_DIAG_Pin */
  GPIO_InitStruct.Pin = X_STOP_Pin|TMC_DIAG_Pin;
  GPIO_InitStruct.Mode = GPIO_MODE_INPUT;
  GPIO_InitStruct.Pull = GPIO_NOPULL;
  HAL_GPIO_Init(GPIOB, &GPIO_InitStruct);

  /*Configure GPIO pin : Y_STOP_Pin */
  GPIO_InitStruct.Pin = Y_STOP_Pin;
  GPIO_InitStruct.Mode = GPIO_MODE_INPUT;
  GPIO_InitStruct.Pull = GPIO_NOPULL;
  HAL_GPIO_Init(Y_STOP_GPIO_Port, &GPIO_InitStruct);

  /*Configure GPIO pin : TMC_S3_Pin */
  GPIO_InitStruct.Pin = TMC_S3_Pin;
  GPIO_InitStruct.Mode = GPIO_MODE_OUTPUT_PP;
  GPIO_InitStruct.Pull = GPIO_NOPULL;
  GPIO_InitStruct.Speed = GPIO_SPEED_FREQ_LOW;
  HAL_GPIO_Init(TMC_S3_GPIO_Port, &GPIO_InitStruct);

}

void Error_Handler(void)
{
  __disable_irq();
  while (1)
  {
  }
}
